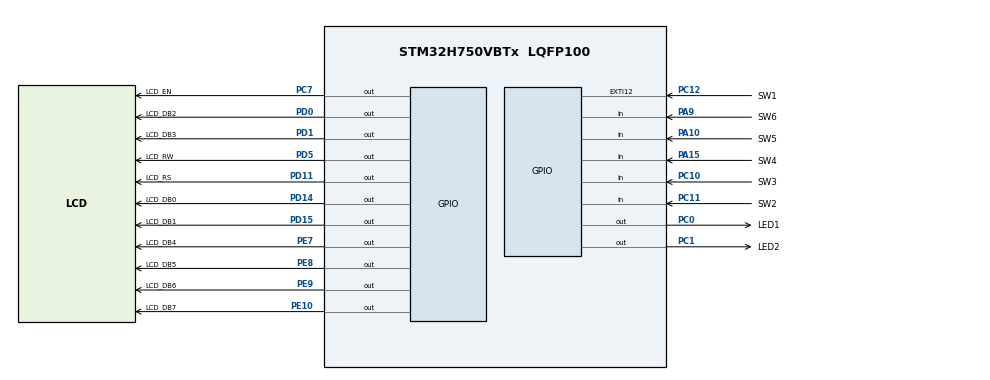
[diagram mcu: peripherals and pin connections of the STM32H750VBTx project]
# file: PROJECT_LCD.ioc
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Mcu.Family=STM32H7
Mcu.Name=STM32H750VBTx
Mcu.Package=LQFP100
NVIC.PriorityGroup=NVIC_PRIORITYGROUP_4
NVIC.TIM8_TRG_COM_TIM14_IRQn=true\:0\:0\:false\:false\:true\:true\:true\:true
PA10.GPIO_Label=SW5
PA10.Signal=GPIO_Input
PA15\ (JTDI).GPIO_Label=SW4
PA15\ (JTDI).Signal=GPIO_Input
PA9.GPIO_Label=SW6
PA9.Signal=GPIO_Input
PC0.GPIO_Label=LED1
PC0.Signal=GPIO_Output
PC1.GPIO_Label=LED2
PC1.Signal=GPIO_Output
PC10.GPIO_Label=SW3
PC10.Signal=GPIO_Input
PC11.GPIO_Label=SW2
PC11.Signal=GPIO_Input
PC12.GPIO_Label=SW1
PC12.Signal=GPXTI12
PC7.GPIO_Label=LCD_EN
PC7.Signal=GPIO_Output
PD0.GPIO_Label=LCD_DB2
PD0.Signal=GPIO_Output
PD1.GPIO_Label=LCD_DB3
PD1.Signal=GPIO_Output
PD11.GPIO_Label=LCD_RS
PD11.Signal=GPIO_Output
PD14.GPIO_Label=LCD_DB0
PD14.Signal=GPIO_Output
PD15.GPIO_Label=LCD_DB1
PD15.Signal=GPIO_Output
PD5.GPIO_Label=LCD_RW
PD5.Signal=GPIO_Output
PE10.GPIO_Label=LCD_DB7
PE10.Signal=GPIO_Output
PE7.GPIO_Label=LCD_DB4
PE7.Signal=GPIO_Output
PE8.GPIO_Label=LCD_DB5
PE8.Signal=GPIO_Output
PE9.GPIO_Label=LCD_DB6
PE9.Signal=GPIO_Output
ProjectManager.HeapSize=0x200
ProjectManager.StackSize=0x400
ProjectManager.TargetToolchain=STM32CubeIDE
RCC.ADCFreq_Value=129000000
RCC.APB1Freq_Value=64000000
RCC.APB2Freq_Value=64000000
RCC.APB3Freq_Value=64000000
RCC.APB4Freq_Value=64000000
RCC.CortexFreq_Value=64000000
RCC.HCLKFreq_Value=64000000
RCC.SYSCLKFreq_VALUE=64000000
RCC.USBFreq_Value=129000000
TIM14.Period=1000
TIM14.Prescaler=63
VP_MEMORYMAP_VS_MEMORYMAP.Mode=CurAppReg
VP_TIM14_VS_ClockSourceINT.Mode=Enable_Timer
board=custom

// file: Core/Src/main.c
/* USER CODE BEGIN Header */
/**
  ******************************************************************************
  * @file           : main.c
  * @brief          : Main program body
  ******************************************************************************
  * @attention
  *
  * Copyright (c) 2026 STMicroelectronics.
  * All rights reserved.
  *
  * This software is licensed under terms that can be found in the LICENSE file
  * in the root directory of this software component.
  * If no LICENSE file comes with this software, it is provided AS-IS.
  *
  ******************************************************************************
  */
/* USER CODE END Header */
#include "main.h"

/* USER CODE BEGIN PM */
int16_t TIMREF;

/* USER CODE END PM */

TIM_HandleTypeDef htim14;

/* USER CODE BEGIN PV */
BUTTON_EVENT Key;
/* USER CODE END PV */

void SystemClock_Config(void);
static void MX_GPIO_Init(void);
static void MX_TIM14_Init(void);
/* USER CODE BEGIN PFP */
//static void Delay_us(uint16_t us);
//static void LCD_Enable(void);
//static void LCD_SENDBYTE(uint8_t data);
//static void LCD_COMMAND(uint8_t cmd);
//static void LCD_DATA(uint8_t data);
//static void LCD_STRING(char *str);
//static void LCD_Init(void);
//static void LCD_STRING(char *str);
/* USER CODE END PFP */

int main(void)
{

  /* MCU Configuration--------------------------------------------------------*/

  /* Reset of all peripherals, Initializes the Flash interface and the Systick. */
  HAL_Init();

  /* Configure the system clock */
  SystemClock_Config();

  /* Initialize all configured peripherals */
  MX_GPIO_Init();
  MX_TIM14_Init();
  /* USER CODE BEGIN 2 */
 // HAL_TIM_Base_Start(&htim14);
  HAL_TIM_Base_Start(&htim14);
  LCD_Init();

  LCD_STRING("INDUSTRIAL HMI");
  LCD_COMMAND(0xC0);
  LCD_STRING("BY: HITA JADHAV");
  /* USER CODE END 2 */

  /* Infinite loop */
  while (1)
  {
//	  Key = Button_Read();
//
//	      if(Key == BTN_MENU)
//	      {
//	          LCD_COMMAND(0x01);
//
//	          LCD_STRING("MENU");
//	      }
//	      if(HAL_GPIO_ReadPin(SW3_GPIO_Port, SW3_Pin) == GPIO_PIN_RESET)
//	      {
//	          LCD_COMMAND(0x01);
//	          LCD_STRING("PRESS");
//
//	          HAL_Delay(500);
//	      }
	  Menu_Task();
    /* USER CODE BEGIN 3 */
//	  LCD_Init();
//
//	  LCD_STRING("HELLO");
  }
  /* USER CODE END 3 */
}

void SystemClock_Config(void)
{
  RCC_OscInitTypeDef RCC_OscInitStruct = {0};
  RCC_ClkInitTypeDef RCC_ClkInitStruct = {0};

  /** Supply configuration update enable
  */
  HAL_PWREx_ConfigSupply(PWR_LDO_SUPPLY);

  /** Configure the main internal regulator output voltage
  */
  __HAL_PWR_VOLTAGESCALING_CONFIG(PWR_REGULATOR_VOLTAGE_SCALE3);

  while(!__HAL_PWR_GET_FLAG(PWR_FLAG_VOSRDY)) {}

  /** Initializes the RCC Oscillators according to the specified parameters
  * in the RCC_OscInitTypeDef structure.
  */
  RCC_OscInitStruct.OscillatorType = RCC_OSCILLATORTYPE_HSI;
  RCC_OscInitStruct.HSIState = RCC_HSI_DIV1;
  RCC_OscInitStruct.HSICalibrationValue = RCC_HSICALIBRATION_DEFAULT;
  RCC_OscInitStruct.PLL.PLLState = RCC_PLL_NONE;
  if (HAL_RCC_OscConfig(&RCC_OscInitStruct) != HAL_OK)
  {
    Error_Handler();
  }

  /** Initializes the CPU, AHB and APB buses clocks
  */
  RCC_ClkInitStruct.ClockType = RCC_CLOCKTYPE_HCLK|RCC_CLOCKTYPE_SYSCLK
                              |RCC_CLOCKTYPE_PCLK1|RCC_CLOCKTYPE_PCLK2
                              |RCC_CLOCKTYPE_D3PCLK1|RCC_CLOCKTYPE_D1PCLK1;
  RCC_ClkInitStruct.SYSCLKSource = RCC_SYSCLKSOURCE_HSI;
  RCC_ClkInitStruct.SYSCLKDivider = RCC_SYSCLK_DIV1;
  RCC_ClkInitStruct.AHBCLKDivider = RCC_HCLK_DIV1;
  RCC_ClkInitStruct.APB3CLKDivider = RCC_APB3_DIV1;
  RCC_ClkInitStruct.APB1CLKDivider = RCC_APB1_DIV1;
  RCC_ClkInitStruct.APB2CLKDivider = RCC_APB2_DIV1;
  RCC_ClkInitStruct.APB4CLKDivider = RCC_APB4_DIV1;

  if (HAL_RCC_ClockConfig(&RCC_ClkInitStruct, FLASH_LATENCY_1) != HAL_OK)
  {
    Error_Handler();
  }
}

static void MX_TIM14_Init(void)
{

  htim14.Instance = TIM14;
  htim14.Init.Prescaler = 63;
  htim14.Init.CounterMode = TIM_COUNTERMODE_UP;
  htim14.Init.Period = 1000;
  htim14.Init.ClockDivision = TIM_CLOCKDIVISION_DIV1;
  htim14.Init.AutoReloadPreload = TIM_AUTORELOAD_PRELOAD_DISABLE;
  if (HAL_TIM_Base_Init(&htim14) != HAL_OK)
  {
    Error_Handler();
  }

}

static void MX_GPIO_Init(void)
{
  GPIO_InitTypeDef GPIO_InitStruct = {0};

  /* GPIO Ports Clock Enable */
  __HAL_RCC_GPIOC_CLK_ENABLE();
  __HAL_RCC_GPIOE_CLK_ENABLE();
  __HAL_RCC_GPIOD_CLK_ENABLE();
  __HAL_RCC_GPIOA_CLK_ENABLE();

  /*Configure GPIO pin Output Level */
  HAL_GPIO_WritePin(GPIOC, LED1_Pin|LED2_Pin|LCD_EN_Pin, GPIO_PIN_RESET);

  /*Configure GPIO pin Output Level */
  HAL_GPIO_WritePin(GPIOE, LCD_DB4_Pin|LCD_DB5_Pin|LCD_DB6_Pin|LCD_DB7_Pin, GPIO_PIN_RESET);

  /*Configure GPIO pin Output Level */
  HAL_GPIO_WritePin(GPIOD, LCD_RS_Pin|LCD_DB0_Pin|LCD_DB1_Pin|LCD_DB2_Pin
                          |LCD_DB3_Pin|LCD_RW_Pin, GPIO_PIN_RESET);

  /*Configure GPIO pins : LED1_Pin LED2_Pin LCD_EN_Pin */
  GPIO_InitStruct.Pin = LED1_Pin|LED2_Pin|LCD_EN_Pin;
  GPIO_InitStruct.Mode = GPIO_MODE_OUTPUT_PP;
  GPIO_InitStruct.Pull = GPIO_NOPULL;
  GPIO_InitStruct.Speed = GPIO_SPEED_FREQ_LOW;
  HAL_GPIO_Init(GPIOC, &GPIO_InitStruct);

  /*Configure GPIO pins : LCD_DB4_Pin LCD_DB5_Pin LCD_DB6_Pin LCD_DB7_Pin */
  GPIO_InitStruct.Pin = LCD_DB4_Pin|LCD_DB5_Pin|LCD_DB6_Pin|LCD_DB7_Pin;
  GPIO_InitStruct.Mode = GPIO_MODE_OUTPUT_PP;
  GPIO_InitStruct.Pull = GPIO_NOPULL;
  GPIO_InitStruct.Speed = GPIO_SPEED_FREQ_LOW;
  HAL_GPIO_Init(GPIOE, &GPIO_InitStruct);

  /*Configure GPIO pins : LCD_RS_Pin LCD_DB0_Pin LCD_DB1_Pin LCD_DB2_Pin
                           LCD_DB3_Pin LCD_RW_Pin */
  GPIO_InitStruct.Pin = LCD_RS_Pin|LCD_DB0_Pin|LCD_DB1_Pin|LCD_DB2_Pin
                          |LCD_DB3_Pin|LCD_RW_Pin;
  GPIO_InitStruct.Mode = GPIO_MODE_OUTPUT_PP;
  GPIO_InitStruct.Pull = GPIO_NOPULL;
  GPIO_InitStruct.Speed = GPIO_SPEED_FREQ_LOW;
  HAL_GPIO_Init(GPIOD, &GPIO_InitStruct);

  /*Configure GPIO pins : SW6_Pin SW5_Pin SW4_Pin */
  GPIO_InitStruct.Pin = SW6_Pin|SW5_Pin|SW4_Pin;
  GPIO_InitStruct.Mode = GPIO_MODE_INPUT;
  GPIO_InitStruct.Pull = GPIO_NOPULL;
  HAL_GPIO_Init(GPIOA, &GPIO_InitStruct);

  /*Configure GPIO pins : SW3_Pin SW2_Pin */
  GPIO_InitStruct.Pin = SW3_Pin|SW2_Pin;
  GPIO_InitStruct.Mode = GPIO_MODE_INPUT;
  GPIO_InitStruct.Pull = GPIO_NOPULL;
  HAL_GPIO_Init(GPIOC, &GPIO_InitStruct);

  /*Configure GPIO pin : SW1_Pin */
  GPIO_InitStruct.Pin = SW1_Pin;
  GPIO_InitStruct.Mode = GPIO_MODE_INPUT;
  GPIO_InitStruct.Pull = GPIO_NOPULL;
  HAL_GPIO_Init(SW1_GPIO_Port, &GPIO_InitStruct);

}

void Error_Handler(void)
{
  __disable_irq();
  while (1)
  {
  }
}
